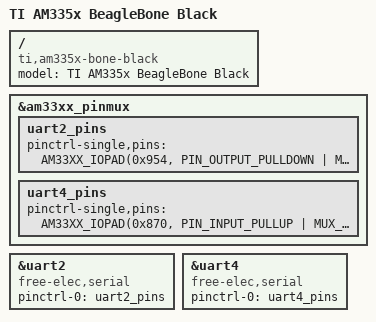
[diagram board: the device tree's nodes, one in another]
/*
 * Copyright (C) 2012 Texas Instruments Incorporated - http://www.ti.com/
 *
 * This program is free software; you can redistribute it and/or modify
 * it under the terms of the GNU General Public License version 2 as
 * published by the Free Software Foundation.
 */
/dts-v1/;

#include "am33xx.dtsi"
#include "am335x-bone-common.dtsi"
#include <dt-bindings/display/tda998x.h>

/ {
	model = "TI AM335x BeagleBone Black";
	compatible = "ti,am335x-bone-black", "ti,am335x-bone", "ti,am33xx";
};

&am33xx_pinmux {
	/* Pins 21 (TX) and 22 (RX) of connector P9 */
	uart2_pins: uart2_pins {
		pinctrl-single,pins = <
			AM33XX_IOPAD(0x954, PIN_OUTPUT_PULLDOWN | MUX_MODE1) /* spi0_d0.uart2_tx */
			AM33XX_IOPAD(0x950, PIN_INPUT_PULLUP | MUX_MODE1) /* spi0_sclk.uart2_rx */
		>;
	};
	
	/* Pins 11 (RX) and 13 (TX) of connector P9 */
	
	uart4_pins: uart4_pins {
		pinctrl-single,pins = <
			AM33XX_IOPAD(0x870, PIN_INPUT_PULLUP | MUX_MODE6) /* gpmc_wait0.uart4_rx */
			AM33XX_IOPAD(0x874, PIN_OUTPUT_PULLDOWN | MUX_MODE6) /* gpmc_wpn.uart4_tx */
		>;
	};
};

&uart2 {
	compatible = "free-elec,serial";
	status = "okay";
	pinctrl-names = "default";
	pinctrl-0 = <&uart2_pins>;
};

&uart4 {
	compatible = "free-elec,serial";
	status = "okay";
	pinctrl-names = "default";
	pinctrl-0 = <&uart4_pins>;
};

